# PAC55XX register map
Vendor: Active-Semi; Series: PAC55XX; File version: 1.0
CPU: CM4 r0p1, little endian, MPU, FPU, vendor SysTick, 3 interrupt priority bits
Registers are 32-bit, read-write, reset 0x0 unless marked. A register's access mark holds for its fields unless they carry their own. Offsets are from the block's base; [hi:lo] are bit positions; {n}, {i} and the like mark numbered series.

## GPTIMERA — General Purpose Timer A (GPTimer A)
Base 0x400B0000
0x00 CTL — GPTimer A Control
0x04 CTR — GPTimer A Counter

## GPTIMERB — General Purpose Timer B (GPTimer B)
Base 0x400C0000
0x00 CTL — GPTimer B Control
0x04 CTR — GPTimer B Counter

## MEMCTL — Memory Controller
Base 0x400D0000
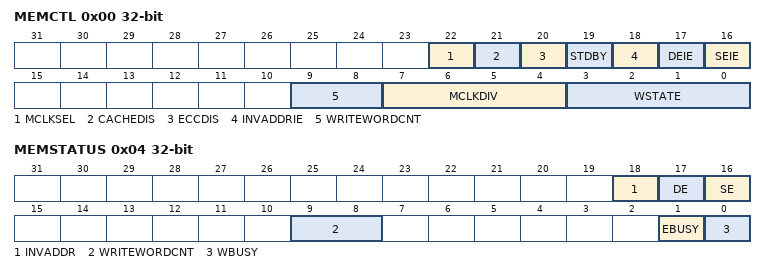
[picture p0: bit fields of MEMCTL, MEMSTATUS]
0x00 MEMCTL — Memory Controller Configuration
  [22] MCLKSEL — MCLK Mux Select
    0=ROSCCLK (ROSC Clock selected as input to MCLK); 1=MCLK (HCLK / MCLKDIV)
  [21] CACHEDIS — FLASH Read Cache Disable
    0=Enabled (FLASH Read Cache Enabled); 1=Disabled (FLASH Read Cache Disabled)
  [20] ECCDIS — SRAM ECC Disable
    0=Enabled (SRAM ECC Enabled); 1=Disabled (SRAM ECC Disabled)
  [19] STDBY — FLASH Standby Mode
    0=Normal Mode; 1=Standby Mode
  [18] INVADDRIE — Invalid Memory Address Access Interrupt Enable
    0=Disabled (Invalid Memory Interrupt Disabled); 1=Enabled (Invalid Memory Interrupt Enabled)
  [17] DEIE — ECC Dual bit Error Interrupt Enable
    0=Disabled (ECC Dual bit Error Interrupt Disabled); 1=Enabled (ECC Dual bit Error Interrupt Enabled)
  [16] SEIE — ECC Single bit Error Interrupt Enable
    0=Disabled (ECC Single bit Error Interrupt Disabled); 1=Enabled (ECC Single bit Error Interrupt Enabled)
  [9:8] WRITEWORDCNT — Write Word Data Count
  [7:4] MCLKDIV — MCLK Divider
    {v}=HCLK /{v+1} (MCLK) (v=0..15)
  [3:0] WSTATE — FLASH Access Wait States
    0=0 WS (0 Wait States); 1=1 WS (1 Wait State); {v}={v} WS ({v} Wait States) (v=2..15)
0x04 MEMSTATUS — Memory Controller Status
  [18] INVADDR — Invalid Memory Address Access Flag
    0=No Flag (No Invalid Memory Flag); 1=Flag (Invalid Memory Flag Set)
  [17] DE — ECC Dual bit Error Detection Flag
    0=No Flag (No ECC Dual bit Error Flag); 1=Flag (ECC Dual bit Error Flag Set)
  [16] SE — ECC Single bit Error Detection Flag
    0=No FLag (No ECC Single bit Error Flag); 1=Flag (ECC Single bit Error Flag Set)
  [9:8] WRITEWORDCNT — Write Word Data Count
  [1] EBUSY — FLASH Erase Busy
    0=Not Busy (FLASH erase operation not in progress); 1=Busy (FLASH erase operation in progress)
  [0] WBUSY — FLASH Write Busy
    0=Not Busy (FLASH write operation not in progress); 1=Busy (FLASH write operation in progress)
0x08 FLASHLOCK — FLASH Lock Access
0x0C FLASHPAGE
0x10 SWDUNLOCK
0x20 FLASHERASE

## WWDT — Windowed Watchdog Timer
Base 0x400D0800
0x00 CTL — WWDT Control
0x04 LOAD — WWDT Load Counter Value
0x08 CTR — WWDT Counter
0x0C INTF — WWDT Interrupt Flag
0x10 INTCLR — WWDT Interrupt Clear
0x14 LOCK — WWDT Lock

## RTC — Real-Time Clock (RTC) with Calendar
Base 0x400D0C00
0x00 CTL — RTC Control
0x04 TIME — RTC Time
0x08 DATE — RTC Date
0x0C TIMESET — RTC Time Setting
0x10 DATESET — RTC Date Setting
0x14 ALARMSET — RTC Alarm Setting

## CRC — CRC Module
Base 0x400D1000
0x00 CTL — CRC Control
0x04 DATAIN — CRC Data Input
0x08 SEED — CRC Seed Value
0x0C DATAOUT — CRC Data Output

## GPIOA
Base 0x400D1400
0x00 MODE — GPIO A Pin Mode Select
0x04 OUTMASK — GPIO A Data Output Write Mask
0x08 OUT — GPIO A Data Output Value
0x0C IN — GPIO A Data Input Value
0x10 INTEN — GPIO A Interrupt Enable
0x14 INTFLAGRAW — GPIO A Interrupt Flag Raw
0x18 INTFLAGMASKED — GPIO A Interrupt Flag Masked
0x1C INTCLEAR — GPIO A Interrupt Clear
0x20 INTTYPE — GPIO A Interrupt Type
0x24 INTVALUE — GPIO A Interrupt Value
0x28 INTEDGEBOTH — GPIO A Interrupt Edge Both
0x2C DEBOUNCE — GPIO A De-bounce Filter
0x30 DOSET — GPIO A Data Output Set
0x34 DOCLEAR — GPIO A Data Output Clear

## GPIOB
Base 0x400D1800
0x00 MODE — GPIO B Pin Mode Select
0x04 OUTMASK — GPIO B Data Output Write Mask
0x08 OUT — GPIO B Data Output Value
0x0C IN — GPIO B Data Input Value
0x10 INTEN — GPIO B Interrupt Enable
0x14 INTFLAGRAW — GPIO B Interrupt Flag Raw
0x18 INTFLAGMASKED — GPIO B Interrupt Flag Masked
0x1C INTCLEAR — GPIO B Interrupt Clear
0x20 INTTYPE — GPIO B Interrupt Type
0x24 INTVALUE — GPIO B Interrupt Value
0x28 INTEDGEBOTH — GPIO B Interrupt Edge Both
0x2C DEBOUNCE — GPIO B De-bounce Filter
0x30 DOSET — GPIO B Data Output Set
0x34 DOCLEAR — GPIO B Data Output Clear

## GPIOC
Base 0x400D1C00
0x00 MODE — GPIO C Pin Mode Select
0x04 OUTMASK — GPIO C Data Output Write Mask
0x08 OUT — GPIO C Data Output Value
0x0C IN — GPIO C Data Input Value
0x10 INTEN — GPIO C Interrupt Enable
0x14 INTFLAGRAW — GPIO C Interrupt Flag Raw
0x18 INTFLAGMASKED — GPIO C Interrupt Flag Masked
0x1C INTCLEAR — GPIO C Interrupt Clear
0x20 INTTYPE — GPIO C Interrupt Type
0x24 INTVALUE — GPIO C Interrupt Value
0x28 INTEDGEBOTH — GPIO C Interrupt Edge Both
0x2C DEBOUNCE — GPIO C De-bounce Filter
0x30 DOSET — GPIO C Data Output Set
0x34 DOCLEAR — GPIO C Data Output Clear

## GPIOD
Base 0x400D2000
0x00 MODE — GPIO D Pin Mode Select
0x04 OUTMASK — GPIO D Data Output Write Mask
0x08 OUT — GPIO D Data Output Value
0x0C IN — GPIO D Data Input Value
0x10 INTEN — GPIO D Interrupt Enable
0x14 INTFLAGRAW — GPIO D Interrupt Flag Raw
0x18 INTFLAGMASKED — GPIO D Interrupt Flag Masked
0x1C INTCLEAR — GPIO D Interrupt Clear
0x20 INTTYPE — GPIO D Interrupt Type
0x24 INTVALUE — GPIO D Interrupt Value
0x28 INTEDGEBOTH — GPIO D Interrupt Edge Both
0x2C DEBOUNCE — GPIO D De-bounce Filter
0x30 DOSET — GPIO D Data Output Set
0x34 DOCLEAR — GPIO D Data Output Clear

## GPIOE
Base 0x400D2400
0x00 MODE — GPIO E Pin Mode Select
0x04 OUTMASK — GPIO E Data Output Write Mask
0x08 OUT — GPIO E Data Output Value
0x0C IN — GPIO E Data Input Value
0x10 INTEN — GPIO E Interrupt Enable
0x14 INTFLAGRAW — GPIO E Interrupt Flag Raw
0x18 INTFLAGMASKED — GPIO E Interrupt Flag Masked
0x1C INTCLEAR — GPIO E Interrupt Clear
0x20 INTTYPE — GPIO E Interrupt Type
0x24 INTVALUE — GPIO E Interrupt Value
0x28 INTEDGEBOTH — GPIO E Interrupt Edge Both
0x2C DEBOUNCE — GPIO E De-bounce Filter
0x30 DOSET — GPIO E Data Output Set
0x34 DOCLEAR — GPIO E Data Output Clear

## GPIOF
Base 0x400D2800
0x00 MODE — GPIO F Pin Mode Select
0x04 OUTMASK — GPIO F Data Output Write Mask
0x08 OUT — GPIO F Data Output Value
0x0C IN — GPIO F Data Input Value
0x10 INTEN — GPIO F Interrupt Enable
0x14 INTFLAGRAW — GPIO F Interrupt Flag Raw
0x18 INTFLAGMASKED — GPIO F Interrupt Flag Masked
0x1C INTCLEAR — GPIO F Interrupt Clear
0x20 INTTYPE — GPIO F Interrupt Type
0x24 INTVALUE — GPIO F Interrupt Value
0x28 INTEDGEBOTH — GPIO F Interrupt Edge Both
0x2C DEBOUNCE — GPIO F De-bounce Filter
0x30 DOSET — GPIO F Data Output Set
0x34 DOCLEAR — GPIO F Data Output Clear

## GPIOG
Base 0x400D2C00
0x00 MODE — GPIO G Pin Mode Select
0x04 OUTMASK — GPIO G Data Output Write Mask
0x08 OUT — GPIO G Data Output Value
0x0C IN — GPIO G Data Input Value
0x10 INTEN — GPIO G Interrupt Enable
0x14 INTFLAGRAW — GPIO G Interrupt Flag Raw
0x18 INTFLAGMASKED — GPIO G Interrupt Flag Masked
0x1C INTCLEAR — GPIO G Interrupt Clear
0x20 INTTYPE — GPIO G Interrupt Type
0x24 INTVALUE — GPIO G Interrupt Value
0x28 INTEDGEBOTH — GPIO G Interrupt Edge Both
0x2C DEBOUNCE — GPIO G De-bounce Filter
0x30 DOSET — GPIO G Data Output Set
0x34 DOCLEAR — GPIO G Data Output Clear
